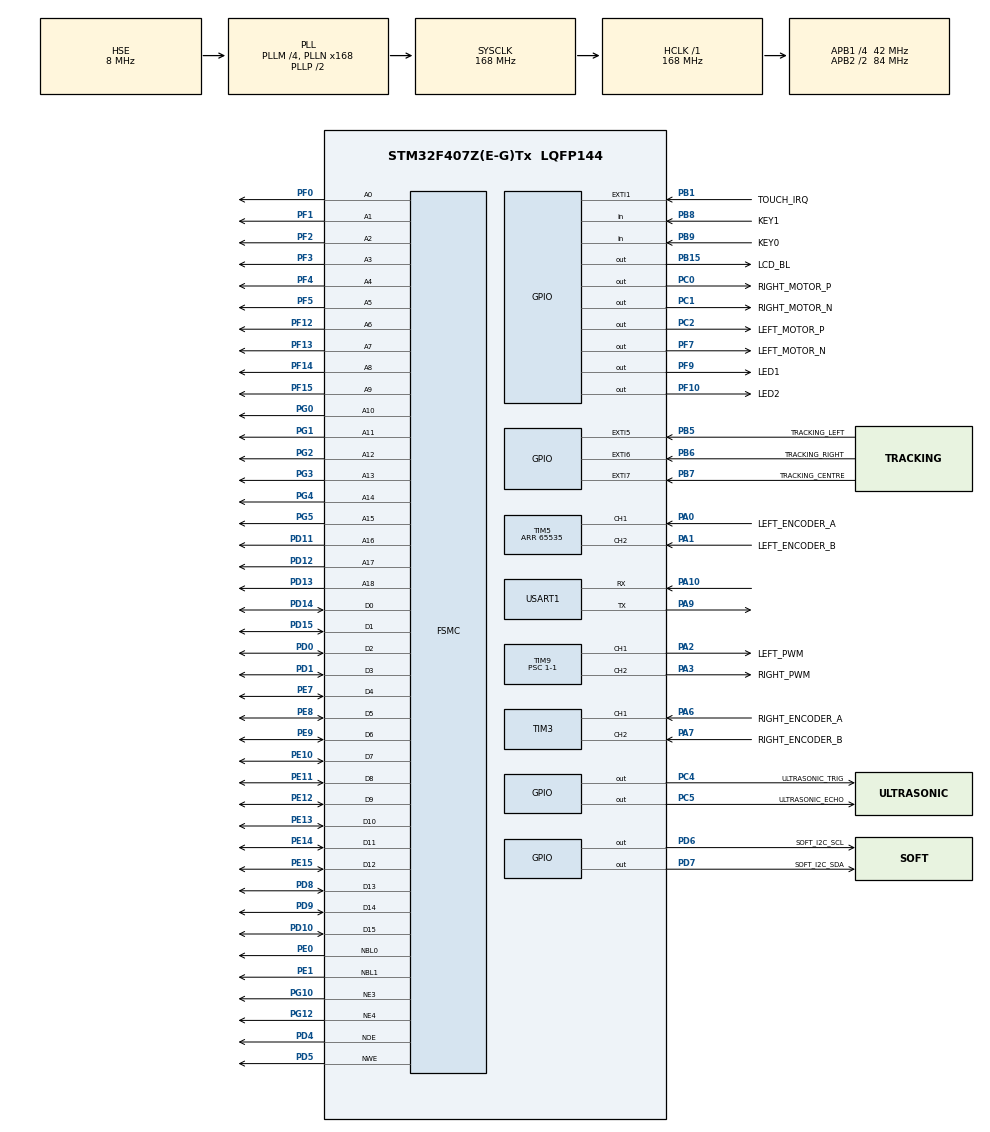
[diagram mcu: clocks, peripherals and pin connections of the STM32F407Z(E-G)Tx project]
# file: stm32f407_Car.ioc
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Dma.MEMTOMEM.0.Direction=DMA_MEMORY_TO_MEMORY
Dma.MEMTOMEM.0.FIFOMode=DMA_FIFOMODE_ENABLE
Dma.MEMTOMEM.0.FIFOThreshold=DMA_FIFO_THRESHOLD_FULL
Dma.MEMTOMEM.0.Instance=DMA2_Stream0
Dma.MEMTOMEM.0.MemBurst=DMA_MBURST_SINGLE
Dma.MEMTOMEM.0.MemDataAlignment=DMA_MDATAALIGN_HALFWORD
Dma.MEMTOMEM.0.MemInc=DMA_MINC_DISABLE
Dma.MEMTOMEM.0.Mode=DMA_NORMAL
Dma.MEMTOMEM.0.PeriphBurst=DMA_PBURST_SINGLE
Dma.MEMTOMEM.0.PeriphDataAlignment=DMA_PDATAALIGN_HALFWORD
Dma.MEMTOMEM.0.PeriphInc=DMA_PINC_ENABLE
Dma.MEMTOMEM.0.Priority=DMA_PRIORITY_HIGH
Dma.MEMTOMEM.1.Direction=DMA_MEMORY_TO_MEMORY
Dma.MEMTOMEM.1.FIFOMode=DMA_FIFOMODE_ENABLE
Dma.MEMTOMEM.1.FIFOThreshold=DMA_FIFO_THRESHOLD_FULL
Dma.MEMTOMEM.1.Instance=DMA2_Stream2
Dma.MEMTOMEM.1.MemBurst=DMA_MBURST_SINGLE
Dma.MEMTOMEM.1.MemDataAlignment=DMA_MDATAALIGN_HALFWORD
Dma.MEMTOMEM.1.MemInc=DMA_MINC_DISABLE
Dma.MEMTOMEM.1.Mode=DMA_NORMAL
Dma.MEMTOMEM.1.PeriphBurst=DMA_PBURST_SINGLE
Dma.MEMTOMEM.1.PeriphDataAlignment=DMA_PDATAALIGN_HALFWORD
Dma.MEMTOMEM.1.PeriphInc=DMA_PINC_ENABLE
Dma.MEMTOMEM.1.Priority=DMA_PRIORITY_HIGH
Dma.MEMTOMEM.2.Direction=DMA_MEMORY_TO_MEMORY
Dma.MEMTOMEM.2.FIFOMode=DMA_FIFOMODE_ENABLE
Dma.MEMTOMEM.2.FIFOThreshold=DMA_FIFO_THRESHOLD_FULL
Dma.MEMTOMEM.2.Instance=DMA2_Stream3
Dma.MEMTOMEM.2.MemBurst=DMA_MBURST_SINGLE
Dma.MEMTOMEM.2.MemDataAlignment=DMA_MDATAALIGN_HALFWORD
Dma.MEMTOMEM.2.MemInc=DMA_MINC_ENABLE
Dma.MEMTOMEM.2.Mode=DMA_NORMAL
Dma.MEMTOMEM.2.PeriphBurst=DMA_PBURST_SINGLE
Dma.MEMTOMEM.2.PeriphDataAlignment=DMA_PDATAALIGN_HALFWORD
Dma.MEMTOMEM.2.PeriphInc=DMA_PINC_ENABLE
Dma.MEMTOMEM.2.Priority=DMA_PRIORITY_HIGH
Dma.Request0=MEMTOMEM
Dma.Request1=MEMTOMEM
Dma.Request2=MEMTOMEM
FREERTOS.BinarySemaphores01=SemUartReceived,Dynamic,NULL
FREERTOS.Tasks01=defaultTask,0,128,StartDefaultTask,Default,NULL,Dynamic,NULL,NULL;DisplayTask,0,1024,StartDisplayTask,As external,NULL,Dynamic,NULL,NULL;UartTask,0,512,StartUartTask,As external,SemUartReceivedHandle,Dynamic,NULL,NULL;LoopTask,0,4096,StartLoopTask,As external,NULL,Dynamic,NULL,NULL;KeyTask,0,128,StartKeyTask,As external,NULL,Dynamic,NULL,NULL;CarTask,0,1024,StartCarTask,As external,NULL,Dynamic,NULL,NULL
FREERTOS.configTOTAL_HEAP_SIZE=32768
FREERTOS.configUSE_NEWLIB_REENTRANT=1
FREERTOS.configUSE_TIMERS=1
FSMC.AddressSetupTime1=5
FSMC.AddressSetupTime2=2
FSMC.BusTurnAroundDuration1=1
FSMC.BusTurnAroundDuration2=1
FSMC.DataSetupTime1=7
FSMC.DataSetupTime2=2
FSMC.ExtendedMode1=FSMC_EXTENDED_MODE_DISABLE
FSMC.WriteOperation1=FSMC_WRITE_OPERATION_ENABLE
Mcu.Family=STM32F4
Mcu.Name=STM32F407Z(E-G)Tx
Mcu.Package=LQFP144
Mcu.UserConstants=ENCODER_TICK_FREQ_DEFAULT,50
NVIC.EXTI1_IRQn=true\:5\:0\:false\:false\:true\:true\:true\:true
NVIC.PriorityGroup=NVIC_PRIORITYGROUP_4
NVIC.TIM1_UP_TIM10_IRQn=true\:15\:0\:false\:false\:true\:false\:false\:true
NVIC.TIM3_IRQn=true\:5\:0\:false\:false\:true\:true\:true\:true
NVIC.TIM5_IRQn=true\:5\:0\:false\:false\:true\:true\:true\:true
NVIC.TIM6_DAC_IRQn=true\:5\:0\:false\:false\:true\:true\:true\:true
NVIC.TIM7_IRQn=true\:5\:0\:false\:false\:true\:true\:true\:true
NVIC.TimeBase=TIM1_UP_TIM10_IRQn
NVIC.TimeBaseIP=TIM10
NVIC.USART1_IRQn=true\:5\:0\:false\:false\:true\:true\:true\:true
PA0-WKUP.GPIO_Label=LEFT_ENCODER_A
PA0-WKUP.GPIO_Speed=GPIO_SPEED_FREQ_VERY_HIGH
PA0-WKUP.Signal=S_TIM5_CH1
PA1.GPIO_Label=LEFT_ENCODER_B
PA1.GPIO_Speed=GPIO_SPEED_FREQ_VERY_HIGH
PA1.Signal=S_TIM5_CH2
PA10.Mode=Asynchronous
PA10.Signal=USART1_RX
PA13.Mode=Serial_Wire
PA13.Signal=SYS_JTMS-SWDIO
PA14.Mode=Serial_Wire
PA14.Signal=SYS_JTCK-SWCLK
PA2.GPIO_Label=LEFT_PWM
PA2.GPIO_Speed=GPIO_SPEED_FREQ_VERY_HIGH
PA2.Signal=S_TIM9_CH1
PA3.GPIO_Label=RIGHT_PWM
PA3.GPIO_Speed=GPIO_SPEED_FREQ_VERY_HIGH
PA3.Signal=S_TIM9_CH2
PA6.GPIO_Label=RIGHT_ENCODER_A
PA6.Signal=S_TIM3_CH1
PA7.GPIO_Label=RIGHT_ENCODER_B
PA7.Signal=S_TIM3_CH2
PA9.Mode=Asynchronous
PA9.Signal=USART1_TX
PB1.GPIO_Label=TOUCH_IRQ
PB1.GPIO_ModeDefaultEXTI=GPIO_MODE_IT_FALLING
PB1.GPIO_PuPd=GPIO_PULLUP
PB1.Signal=GPXTI1
PB15.GPIO_Label=LCD_BL
PB15.PinState=GPIO_PIN_RESET
PB15.Signal=GPIO_Output
PB5.GPIO_Label=TRACKING_LEFT
PB5.Signal=GPXTI5
PB6.GPIO_Label=TRACKING_RIGHT
PB6.Signal=GPXTI6
PB7.GPIO_Label=TRACKING_CENTRE
PB7.GPIO_ModeDefaultEXTI=GPIO_MODE_IT_FALLING
PB7.Signal=GPXTI7
PB8.GPIO_Label=KEY1
PB8.GPIO_PuPd=GPIO_PULLUP
PB8.Signal=GPIO_Input
PB9.GPIO_Label=KEY0
PB9.GPIO_PuPd=GPIO_PULLUP
PB9.Signal=GPIO_Input
PC0.GPIO_Label=RIGHT_MOTOR_P
PC0.GPIO_Speed=GPIO_SPEED_FREQ_HIGH
PC0.Signal=GPIO_Output
PC1.GPIO_Label=RIGHT_MOTOR_N
PC1.GPIO_Speed=GPIO_SPEED_FREQ_HIGH
PC1.Signal=GPIO_Output
PC14-OSC32_IN.Mode=LSE-External-Oscillator
PC14-OSC32_IN.Signal=RCC_OSC32_IN
PC15-OSC32_OUT.Mode=LSE-External-Oscillator
PC15-OSC32_OUT.Signal=RCC_OSC32_OUT
PC2.GPIO_Label=LEFT_MOTOR_P
PC2.Signal=GPIO_Output
PC4.GPIO_Label=ULTRASONIC_TRIG
PC4.GPIO_Speed=GPIO_SPEED_FREQ_HIGH
PC4.Signal=GPIO_Output
PC5.GPIO_Label=ULTRASONIC_ECHO
PC5.GPIO_Speed=GPIO_SPEED_FREQ_HIGH
PC5.Signal=GPIO_Output
PD0.Signal=FSMC_D2_DA2
PD1.Signal=FSMC_D3_DA3
PD10.Signal=FSMC_D15_DA15
PD11.Signal=FSMC_A16_CLE
PD12.Signal=FSMC_A17_ALE
PD13.Signal=FSMC_A18
PD14.Signal=FSMC_D0_DA0
PD15.Signal=FSMC_D1_DA1
PD4.Signal=FSMC_NOE
PD5.Signal=FSMC_NWE
PD6.GPIO_Label=SOFT_I2C_SCL
PD6.GPIO_ModeDefaultOutputPP=GPIO_MODE_OUTPUT_OD
PD6.GPIO_Speed=GPIO_SPEED_FREQ_VERY_HIGH
PD6.PinState=GPIO_PIN_SET
PD6.Signal=GPIO_Output
PD7.GPIO_Label=SOFT_I2C_SDA
PD7.GPIO_ModeDefaultOutputPP=GPIO_MODE_OUTPUT_OD
PD7.GPIO_Speed=GPIO_SPEED_FREQ_VERY_HIGH
PD7.PinState=GPIO_PIN_SET
PD7.Signal=GPIO_Output
PD8.Signal=FSMC_D13_DA13
PD9.Signal=FSMC_D14_DA14
PE0.Signal=FSMC_NBL0
PE1.Signal=FSMC_NBL1
PE10.Signal=FSMC_D7_DA7
PE11.Signal=FSMC_D8_DA8
PE12.Signal=FSMC_D9_DA9
PE13.Signal=FSMC_D10_DA10
PE14.Signal=FSMC_D11_DA11
PE15.Signal=FSMC_D12_DA12
PE7.Signal=FSMC_D4_DA4
PE8.Signal=FSMC_D5_DA5
PE9.Signal=FSMC_D6_DA6
PF0.Signal=FSMC_A0
PF1.Signal=FSMC_A1
PF10.GPIO_Label=LED2
PF10.PinState=GPIO_PIN_SET
PF10.Signal=GPIO_Output
PF12.Signal=FSMC_A6
PF13.Signal=FSMC_A7
PF14.Signal=FSMC_A8
PF15.Signal=FSMC_A9
PF2.Signal=FSMC_A2
PF3.Signal=FSMC_A3
PF4.Signal=FSMC_A4
PF5.Signal=FSMC_A5
PF7.GPIO_Label=LEFT_MOTOR_N
PF7.Signal=GPIO_Output
PF9.GPIO_Label=LED1
PF9.PinState=GPIO_PIN_SET
PF9.Signal=GPIO_Output
PG0.Signal=FSMC_A10
PG1.Signal=FSMC_A11
PG10.Mode=NorPsramChipSelect3_1
PG10.Signal=FSMC_NE3
PG12.Mode=NorPsramChipSelect4_2
PG12.Signal=FSMC_NE4
PG2.Signal=FSMC_A12
PG3.Signal=FSMC_A13
PG4.Signal=FSMC_A14
PG5.Signal=FSMC_A15
PH0-OSC_IN.Mode=HSE-External-Oscillator
PH0-OSC_IN.Signal=RCC_OSC_IN
PH1-OSC_OUT.Mode=HSE-External-Oscillator
PH1-OSC_OUT.Signal=RCC_OSC_OUT
ProjectManager.HeapSize=0x200
ProjectManager.StackSize=0x1000
ProjectManager.TargetToolchain=STM32CubeIDE
RCC.48MHZClocksFreq_Value=84000000
RCC.AHBFreq_Value=168000000
RCC.APB1CLKDivider=RCC_HCLK_DIV4
RCC.APB1Freq_Value=42000000
RCC.APB1TimFreq_Value=84000000
RCC.APB2CLKDivider=RCC_HCLK_DIV2
RCC.APB2Freq_Value=84000000
RCC.APB2TimFreq_Value=168000000
RCC.CortexFreq_Value=168000000
RCC.HCLKFreq_Value=168000000
RCC.HSE_VALUE=8000000
RCC.HSI_VALUE=16000000
RCC.PLLM=4
RCC.PLLN=168
RCC.PLLSourceVirtual=RCC_PLLSOURCE_HSE
RCC.RCC_RTC_Clock_SourceVirtual=RCC_RTCCLKSOURCE_LSE
RCC.SYSCLKFreq_VALUE=168000000
RCC.SYSCLKSource=RCC_SYSCLKSOURCE_PLLCLK
RCC.VCOOutputFreq_Value=336000000
RTC.Date=1
RTC.Format=RTC_FORMAT_BIN
RTC.Hours=10
RTC.Month=RTC_MONTH_JANUARY
RTC.WeekDay=RTC_WEEKDAY_MONDAY
RTC.Year=21
SH.FSMC_A0.0=FSMC_A0,19b-a1
SH.FSMC_A1.0=FSMC_A1,19b-a1
SH.FSMC_A10.0=FSMC_A10,19b-a1
SH.FSMC_A11.0=FSMC_A11,19b-a1
SH.FSMC_A12.0=FSMC_A12,19b-a1
SH.FSMC_A13.0=FSMC_A13,19b-a1
SH.FSMC_A14.0=FSMC_A14,19b-a1
SH.FSMC_A15.0=FSMC_A15,19b-a1
SH.FSMC_A16_CLE.0=FSMC_A16,19b-a1
SH.FSMC_A17_ALE.0=FSMC_A17,19b-a1
SH.FSMC_A18.0=FSMC_A18,19b-a1
SH.FSMC_A2.0=FSMC_A2,19b-a1
SH.FSMC_A3.0=FSMC_A3,19b-a1
SH.FSMC_A4.0=FSMC_A4,19b-a1
SH.FSMC_A5.0=FSMC_A5,19b-a1
SH.FSMC_A6.0=FSMC_A6,19b-a1
SH.FSMC_A6.1=FSMC_A6,A6_2
SH.FSMC_A7.0=FSMC_A7,19b-a1
SH.FSMC_A8.0=FSMC_A8,19b-a1
SH.FSMC_A9.0=FSMC_A9,19b-a1
SH.FSMC_D0_DA0.0=FSMC_D0,16b-d1
SH.FSMC_D0_DA0.1=FSMC_D0,16b-d2
SH.FSMC_D10_DA10.0=FSMC_D10,16b-d1
SH.FSMC_D10_DA10.1=FSMC_D10,16b-d2
SH.FSMC_D11_DA11.0=FSMC_D11,16b-d1
SH.FSMC_D11_DA11.1=FSMC_D11,16b-d2
SH.FSMC_D12_DA12.0=FSMC_D12,16b-d1
SH.FSMC_D12_DA12.1=FSMC_D12,16b-d2
SH.FSMC_D13_DA13.0=FSMC_D13,16b-d1
SH.FSMC_D13_DA13.1=FSMC_D13,16b-d2
SH.FSMC_D14_DA14.0=FSMC_D14,16b-d1
SH.FSMC_D14_DA14.1=FSMC_D14,16b-d2
SH.FSMC_D15_DA15.0=FSMC_D15,16b-d1
SH.FSMC_D15_DA15.1=FSMC_D15,16b-d2
SH.FSMC_D1_DA1.0=FSMC_D1,16b-d1
SH.FSMC_D1_DA1.1=FSMC_D1,16b-d2
SH.FSMC_D2_DA2.0=FSMC_D2,16b-d1
SH.FSMC_D2_DA2.1=FSMC_D2,16b-d2
SH.FSMC_D3_DA3.0=FSMC_D3,16b-d1
SH.FSMC_D3_DA3.1=FSMC_D3,16b-d2
SH.FSMC_D4_DA4.0=FSMC_D4,16b-d1
SH.FSMC_D4_DA4.1=FSMC_D4,16b-d2
SH.FSMC_D5_DA5.0=FSMC_D5,16b-d1
SH.FSMC_D5_DA5.1=FSMC_D5,16b-d2
SH.FSMC_D6_DA6.0=FSMC_D6,16b-d1
SH.FSMC_D6_DA6.1=FSMC_D6,16b-d2
SH.FSMC_D7_DA7.0=FSMC_D7,16b-d1
SH.FSMC_D7_DA7.1=FSMC_D7,16b-d2
SH.FSMC_D8_DA8.0=FSMC_D8,16b-d1
SH.FSMC_D8_DA8.1=FSMC_D8,16b-d2
SH.FSMC_D9_DA9.0=FSMC_D9,16b-d1
SH.FSMC_D9_DA9.1=FSMC_D9,16b-d2
SH.FSMC_NBL0.0=FSMC_NBL0,2ByteEnable1
SH.FSMC_NBL1.0=FSMC_NBL1,2ByteEnable1
SH.FSMC_NOE.0=FSMC_NOE,Sram1
SH.FSMC_NOE.1=FSMC_NOE,Lcd2
SH.FSMC_NWE.0=FSMC_NWE,Sram1
SH.FSMC_NWE.1=FSMC_NWE,Lcd2
SH.S_TIM3_CH1.0=TIM3_CH1,Encoder_Interface
SH.S_TIM3_CH2.0=TIM3_CH2,Encoder_Interface
SH.S_TIM5_CH1.0=TIM5_CH1,Encoder_Interface
SH.S_TIM5_CH2.0=TIM5_CH2,Encoder_Interface
SH.S_TIM9_CH1.0=TIM9_CH1,PWM Generation1 CH1
SH.S_TIM9_CH2.0=TIM9_CH2,PWM Generation2 CH2
STMicroelectronics.X-CUBE-TOUCHGFX.4.17.0.tgfx_address1=0x68000000
STMicroelectronics.X-CUBE-TOUCHGFX.4.17.0.tgfx_address2=0x68032000
STMicroelectronics.X-CUBE-TOUCHGFX.4.17.0.tgfx_buffering_strategy=Double
STMicroelectronics.X-CUBE-TOUCHGFX.4.17.0.tgfx_custom_height=400
STMicroelectronics.X-CUBE-TOUCHGFX.4.17.0.tgfx_custom_width=240
STMicroelectronics.X-CUBE-TOUCHGFX.4.17.0.tgfx_datareader=Disabled
STMicroelectronics.X-CUBE-TOUCHGFX.4.17.0.tgfx_display_interface=disp_fmc
STMicroelectronics.X-CUBE-TOUCHGFX.4.17.0.tgfx_fmc_base_address=0x6000007E
STMicroelectronics.X-CUBE-TOUCHGFX.4.17.0.tgfx_location=By Address
STMicroelectronics.X-CUBE-TOUCHGFX.4.17.0_IsPackSelfContextualization=true
TIM3.AutoReloadPreload=TIM_AUTORELOAD_PRELOAD_ENABLE
TIM3.EncoderMode=TIM_ENCODERMODE_TI12
TIM3.IC2Polarity=TIM_ICPOLARITY_RISING
TIM3.TIM_MasterOutputTrigger=TIM_TRGO_RESET
TIM5.AutoReloadPreload=TIM_AUTORELOAD_PRELOAD_ENABLE
TIM5.EncoderMode=TIM_ENCODERMODE_TI12
TIM5.IC2Polarity=TIM_ICPOLARITY_RISING
TIM5.Period=65535
TIM5.TIM_MasterOutputTrigger=TIM_TRGO_RESET
TIM6.AutoReloadPreload=TIM_AUTORELOAD_PRELOAD_ENABLE
TIM6.Period=ENCODER_TICK_FREQ_DEFAULT*10-1
TIM6.Prescaler=8400-1
TIM6.TIM_MasterOutputTrigger=TIM_TRGO_RESET
TIM7.AutoReloadPreload=TIM_AUTORELOAD_PRELOAD_ENABLE
TIM7.Prescaler=84-1
TIM7.TIM_MasterOutputTrigger=TIM_TRGO_UPDATE
TIM9.AutoReloadPreload=TIM_AUTORELOAD_PRELOAD_ENABLE
TIM9.Channel-PWM\ Generation1\ CH1=TIM_CHANNEL_1
TIM9.Channel-PWM\ Generation2\ CH2=TIM_CHANNEL_2
TIM9.Period=5600-1
TIM9.Prescaler=1-1
TIM9.Pulse-PWM\ Generation1\ CH1=0
TIM9.Pulse-PWM\ Generation2\ CH2=0
USART1.VirtualMode=VM_ASYNC
VP_FREERTOS_VS_CMSIS_V1.Mode=CMSIS_V1
VP_RTC_VS_RTC_Activate.Mode=RTC_Enabled
VP_RTC_VS_RTC_Calendar.Mode=RTC_Calendar
VP_SYS_VS_tim10.Mode=TIM10
VP_TIM6_VS_ClockSourceINT.Mode=Enable_Timer
VP_TIM7_VS_ClockSourceINT.Mode=Enable_Timer
board=custom

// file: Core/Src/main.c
/* USER CODE BEGIN Header */
/**
  ******************************************************************************
  * @file           : main.c
  * @brief          : Main program body
  ******************************************************************************
  * @attention
  *
  * <h2><center>&copy; Copyright (c) 2021 STMicroelectronics.
  * All rights reserved.</center></h2>
  *
  * This software component is licensed by ST under Ultimate Liberty license
  * SLA0044, the "License"; You may not use this file except in compliance with
  * the License. You may obtain a copy of the License at:
  *                             www.st.com/SLA0044
  *
  ******************************************************************************
  */
/* USER CODE END Header */
#include "main.h"
#include "cmsis_os.h"

/* USER CODE BEGIN Includes */
#include "mainpp.hpp"

/* USER CODE END Includes */

RTC_HandleTypeDef hrtc;

TIM_HandleTypeDef htim3;
TIM_HandleTypeDef htim5;
TIM_HandleTypeDef htim6;
TIM_HandleTypeDef htim7;
TIM_HandleTypeDef htim9;

UART_HandleTypeDef huart1;

DMA_HandleTypeDef hdma_memtomem_dma2_stream0;
DMA_HandleTypeDef hdma_memtomem_dma2_stream2;
DMA_HandleTypeDef hdma_memtomem_dma2_stream3;
SRAM_HandleTypeDef hsram1;
SRAM_HandleTypeDef hsram2;

osThreadId defaultTaskHandle;
osThreadId DisplayTaskHandle;
osThreadId UartTaskHandle;
osThreadId LoopTaskHandle;
osThreadId KeyTaskHandle;
osThreadId CarTaskHandle;
osSemaphoreId SemUartReceivedHandle;
/* USER CODE BEGIN PV */
//DCMI_HandleTypeDef *DCMI_Handle = &hdcmi;
RTC_HandleTypeDef *RtcHandle = &hrtc;
//I2C_HandleTypeDef *I2C_Handle = &hi2c1;
TIM_HandleTypeDef *usDelay_timer_Handle = &htim7;
UART_HandleTypeDef *UartHandle = &huart1;

Encoder_HandleTypeDef *RIGHT_encoder = &htim3;
Encoder_HandleTypeDef *LEFT_encoder = &htim5;
PWM_HandleTypeDef *LEFT_motor_pwm = &htim9;
PWM_HandleTypeDef *RIGHT_motor_pwm = &htim9;
TIM_HandleTypeDef *encoder_timer = &htim6;

/* USER CODE END PV */

void SystemClock_Config(void);
static void MX_GPIO_Init(void);
static void MX_TIM5_Init(void);
static void MX_FSMC_Init(void);
static void MX_TIM9_Init(void);
static void MX_DMA_Init(void);
static void MX_TIM7_Init(void);
static void MX_RTC_Init(void);
static void MX_TIM6_Init(void);
static void MX_USART1_UART_Init(void);
static void MX_TIM3_Init(void);
void StartDefaultTask(void const * argument);
extern void StartDisplayTask(void const * argument);
extern void StartUartTask(void const * argument);
extern void StartLoopTask(void const * argument);
extern void StartKeyTask(void const * argument);
extern void StartCarTask(void const * argument);

int main(void)
{

  /* MCU Configuration--------------------------------------------------------*/

  /* Reset of all peripherals, Initializes the Flash interface and the Systick. */
  HAL_Init();

  /* Configure the system clock */
  SystemClock_Config();

  /* Initialize all configured peripherals */
  MX_GPIO_Init();
  MX_TIM5_Init();
  MX_FSMC_Init();
  MX_TIM9_Init();
  MX_DMA_Init();
  MX_TIM7_Init();
  MX_RTC_Init();
  MX_TIM6_Init();
  MX_USART1_UART_Init();
  MX_TIM3_Init();
  /* USER CODE BEGIN 2 */
  setup();
  /* USER CODE END 2 */

  /* Create the semaphores(s) */
  /* definition and creation of SemUartReceived */
  osSemaphoreDef(SemUartReceived);
  SemUartReceivedHandle = osSemaphoreCreate(osSemaphore(SemUartReceived), 1);

  /* Create the thread(s) */
  /* definition and creation of defaultTask */
  osThreadDef(defaultTask, StartDefaultTask, osPriorityNormal, 0, 128);
  defaultTaskHandle = osThreadCreate(osThread(defaultTask), NULL);

  /* definition and creation of DisplayTask */
  osThreadDef(DisplayTask, StartDisplayTask, osPriorityNormal, 0, 1024);
  DisplayTaskHandle = osThreadCreate(osThread(DisplayTask), NULL);

  /* definition and creation of UartTask */
  osThreadDef(UartTask, StartUartTask, osPriorityNormal, 0, 512);
  UartTaskHandle = osThreadCreate(osThread(UartTask), (void*) SemUartReceivedHandle);

  /* definition and creation of LoopTask */
  osThreadDef(LoopTask, StartLoopTask, osPriorityNormal, 0, 4096);
  LoopTaskHandle = osThreadCreate(osThread(LoopTask), NULL);

  /* definition and creation of KeyTask */
  osThreadDef(KeyTask, StartKeyTask, osPriorityNormal, 0, 128);
  KeyTaskHandle = osThreadCreate(osThread(KeyTask), NULL);

  /* definition and creation of CarTask */
  osThreadDef(CarTask, StartCarTask, osPriorityNormal, 0, 1024);
  CarTaskHandle = osThreadCreate(osThread(CarTask), NULL);

  /* Start scheduler */
  osKernelStart();

  /* We should never get here as control is now taken by the scheduler */
  /* Infinite loop */
  while (1)
  {

  }
}

void SystemClock_Config(void)
{
  RCC_OscInitTypeDef RCC_OscInitStruct = {0};
  RCC_ClkInitTypeDef RCC_ClkInitStruct = {0};

  /** Configure the main internal regulator output voltage
  */
  __HAL_RCC_PWR_CLK_ENABLE();
  __HAL_PWR_VOLTAGESCALING_CONFIG(PWR_REGULATOR_VOLTAGE_SCALE1);
  /** Initializes the RCC Oscillators according to the specified parameters
  * in the RCC_OscInitTypeDef structure.
  */
  RCC_OscInitStruct.OscillatorType = RCC_OSCILLATORTYPE_HSE|RCC_OSCILLATORTYPE_LSE;
  RCC_OscInitStruct.HSEState = RCC_HSE_ON;
  RCC_OscInitStruct.LSEState = RCC_LSE_ON;
  RCC_OscInitStruct.PLL.PLLState = RCC_PLL_ON;
  RCC_OscInitStruct.PLL.PLLSource = RCC_PLLSOURCE_HSE;
  RCC_OscInitStruct.PLL.PLLM = 4;
  RCC_OscInitStruct.PLL.PLLN = 168;
  RCC_OscInitStruct.PLL.PLLP = RCC_PLLP_DIV2;
  RCC_OscInitStruct.PLL.PLLQ = 4;
  if (HAL_RCC_OscConfig(&RCC_OscInitStruct) != HAL_OK)
  {
    Error_Handler();
  }
  /** Initializes the CPU, AHB and APB buses clocks
  */
  RCC_ClkInitStruct.ClockType = RCC_CLOCKTYPE_HCLK|RCC_CLOCKTYPE_SYSCLK
                              |RCC_CLOCKTYPE_PCLK1|RCC_CLOCKTYPE_PCLK2;
  RCC_ClkInitStruct.SYSCLKSource = RCC_SYSCLKSOURCE_PLLCLK;
  RCC_ClkInitStruct.AHBCLKDivider = RCC_SYSCLK_DIV1;
  RCC_ClkInitStruct.APB1CLKDivider = RCC_HCLK_DIV4;
  RCC_ClkInitStruct.APB2CLKDivider = RCC_HCLK_DIV2;

  if (HAL_RCC_ClockConfig(&RCC_ClkInitStruct, FLASH_LATENCY_5) != HAL_OK)
  {
    Error_Handler();
  }
}

static void MX_RTC_Init(void)
{

  RTC_TimeTypeDef sTime = {0};
  RTC_DateTypeDef sDate = {0};

  /** Initialize RTC Only
  */
  hrtc.Instance = RTC;
  hrtc.Init.HourFormat = RTC_HOURFORMAT_24;
  hrtc.Init.AsynchPrediv = 127;
  hrtc.Init.SynchPrediv = 255;
  hrtc.Init.OutPut = RTC_OUTPUT_DISABLE;
  hrtc.Init.OutPutPolarity = RTC_OUTPUT_POLARITY_HIGH;
  hrtc.Init.OutPutType = RTC_OUTPUT_TYPE_OPENDRAIN;
  if (HAL_RTC_Init(&hrtc) != HAL_OK)
  {
    Error_Handler();
  }

  /** Initialize RTC and set the Time and Date
  */
  sTime.Hours = 10;
  sTime.Minutes = 0;
  sTime.Seconds = 0;
  sTime.DayLightSaving = RTC_DAYLIGHTSAVING_NONE;
  sTime.StoreOperation = RTC_STOREOPERATION_RESET;
  if (HAL_RTC_SetTime(&hrtc, &sTime, RTC_FORMAT_BIN) != HAL_OK)
  {
    Error_Handler();
  }
  sDate.WeekDay = RTC_WEEKDAY_MONDAY;
  sDate.Month = RTC_MONTH_JANUARY;
  sDate.Date = 1;
  sDate.Year = 21;

  if (HAL_RTC_SetDate(&hrtc, &sDate, RTC_FORMAT_BIN) != HAL_OK)
  {
    Error_Handler();
  }

}

static void MX_TIM3_Init(void)
{

  TIM_Encoder_InitTypeDef sConfig = {0};
  TIM_MasterConfigTypeDef sMasterConfig = {0};

  htim3.Instance = TIM3;
  htim3.Init.Prescaler = 0;
  htim3.Init.CounterMode = TIM_COUNTERMODE_UP;
  htim3.Init.Period = 65535;
  htim3.Init.ClockDivision = TIM_CLOCKDIVISION_DIV1;
  htim3.Init.AutoReloadPreload = TIM_AUTORELOAD_PRELOAD_ENABLE;
  sConfig.EncoderMode = TIM_ENCODERMODE_TI12;
  sConfig.IC1Polarity = TIM_ICPOLARITY_RISING;
  sConfig.IC1Selection = TIM_ICSELECTION_DIRECTTI;
  sConfig.IC1Prescaler = TIM_ICPSC_DIV1;
  sConfig.IC1Filter = 0;
  sConfig.IC2Polarity = TIM_ICPOLARITY_RISING;
  sConfig.IC2Selection = TIM_ICSELECTION_DIRECTTI;
  sConfig.IC2Prescaler = TIM_ICPSC_DIV1;
  sConfig.IC2Filter = 0;
  if (HAL_TIM_Encoder_Init(&htim3, &sConfig) != HAL_OK)
  {
    Error_Handler();
  }
  sMasterConfig.MasterOutputTrigger = TIM_TRGO_RESET;
  sMasterConfig.MasterSlaveMode = TIM_MASTERSLAVEMODE_DISABLE;
  if (HAL_TIMEx_MasterConfigSynchronization(&htim3, &sMasterConfig) != HAL_OK)
  {
    Error_Handler();
  }

}

static void MX_TIM5_Init(void)
{

  TIM_Encoder_InitTypeDef sConfig = {0};
  TIM_MasterConfigTypeDef sMasterConfig = {0};

  htim5.Instance = TIM5;
  htim5.Init.Prescaler = 0;
  htim5.Init.CounterMode = TIM_COUNTERMODE_UP;
  htim5.Init.Period = 65535;
  htim5.Init.ClockDivision = TIM_CLOCKDIVISION_DIV1;
  htim5.Init.AutoReloadPreload = TIM_AUTORELOAD_PRELOAD_ENABLE;
  sConfig.EncoderMode = TIM_ENCODERMODE_TI12;
  sConfig.IC1Polarity = TIM_ICPOLARITY_RISING;
  sConfig.IC1Selection = TIM_ICSELECTION_DIRECTTI;
  sConfig.IC1Prescaler = TIM_ICPSC_DIV1;
  sConfig.IC1Filter = 0;
  sConfig.IC2Polarity = TIM_ICPOLARITY_RISING;
  sConfig.IC2Selection = TIM_ICSELECTION_DIRECTTI;
  sConfig.IC2Prescaler = TIM_ICPSC_DIV1;
  sConfig.IC2Filter = 0;
  if (HAL_TIM_Encoder_Init(&htim5, &sConfig) != HAL_OK)
  {
    Error_Handler();
  }
  sMasterConfig.MasterOutputTrigger = TIM_TRGO_RESET;
  sMasterConfig.MasterSlaveMode = TIM_MASTERSLAVEMODE_DISABLE;
  if (HAL_TIMEx_MasterConfigSynchronization(&htim5, &sMasterConfig) != HAL_OK)
  {
    Error_Handler();
  }

}

static void MX_TIM6_Init(void)
{

  TIM_MasterConfigTypeDef sMasterConfig = {0};

  htim6.Instance = TIM6;
  htim6.Init.Prescaler = 8400-1;
  htim6.Init.CounterMode = TIM_COUNTERMODE_UP;
  htim6.Init.Period = ENCODER_TICK_FREQ_DEFAULT*10-1;
  htim6.Init.AutoReloadPreload = TIM_AUTORELOAD_PRELOAD_ENABLE;
  if (HAL_TIM_Base_Init(&htim6) != HAL_OK)
  {
    Error_Handler();
  }
  sMasterConfig.MasterOutputTrigger = TIM_TRGO_RESET;
  sMasterConfig.MasterSlaveMode = TIM_MASTERSLAVEMODE_DISABLE;
  if (HAL_TIMEx_MasterConfigSynchronization(&htim6, &sMasterConfig) != HAL_OK)
  {
    Error_Handler();
  }

}

static void MX_TIM7_Init(void)
{

  TIM_MasterConfigTypeDef sMasterConfig = {0};

  htim7.Instance = TIM7;
  htim7.Init.Prescaler = 84-1;
  htim7.Init.CounterMode = TIM_COUNTERMODE_UP;
  htim7.Init.Period = 65535;
  htim7.Init.AutoReloadPreload = TIM_AUTORELOAD_PRELOAD_ENABLE;
  if (HAL_TIM_Base_Init(&htim7) != HAL_OK)
  {
    Error_Handler();
  }
  sMasterConfig.MasterOutputTrigger = TIM_TRGO_UPDATE;
  sMasterConfig.MasterSlaveMode = TIM_MASTERSLAVEMODE_DISABLE;
  if (HAL_TIMEx_MasterConfigSynchronization(&htim7, &sMasterConfig) != HAL_OK)
  {
    Error_Handler();
  }

}

static void MX_TIM9_Init(void)
{

  TIM_OC_InitTypeDef sConfigOC = {0};

  htim9.Instance = TIM9;
  htim9.Init.Prescaler = 1-1;
  htim9.Init.CounterMode = TIM_COUNTERMODE_UP;
  htim9.Init.Period = 5600-1;
  htim9.Init.ClockDivision = TIM_CLOCKDIVISION_DIV1;
  htim9.Init.AutoReloadPreload = TIM_AUTORELOAD_PRELOAD_ENABLE;
  if (HAL_TIM_PWM_Init(&htim9) != HAL_OK)
  {
    Error_Handler();
  }
  sConfigOC.OCMode = TIM_OCMODE_PWM1;
  sConfigOC.Pulse = 0;
  sConfigOC.OCPolarity = TIM_OCPOLARITY_HIGH;
  sConfigOC.OCFastMode = TIM_OCFAST_DISABLE;
  if (HAL_TIM_PWM_ConfigChannel(&htim9, &sConfigOC, TIM_CHANNEL_1) != HAL_OK)
  {
    Error_Handler();
  }
  if (HAL_TIM_PWM_ConfigChannel(&htim9, &sConfigOC, TIM_CHANNEL_2) != HAL_OK)
  {
    Error_Handler();
  }
  HAL_TIM_MspPostInit(&htim9);

}

static void MX_USART1_UART_Init(void)
{

  huart1.Instance = USART1;
  huart1.Init.BaudRate = 115200;
  huart1.Init.WordLength = UART_WORDLENGTH_8B;
  huart1.Init.StopBits = UART_STOPBITS_1;
  huart1.Init.Parity = UART_PARITY_NONE;
  huart1.Init.Mode = UART_MODE_TX_RX;
  huart1.Init.HwFlowCtl = UART_HWCONTROL_NONE;
  huart1.Init.OverSampling = UART_OVERSAMPLING_16;
  if (HAL_UART_Init(&huart1) != HAL_OK)
  {
    Error_Handler();
  }

}

static void MX_DMA_Init(void)
{

  /* DMA controller clock enable */
  __HAL_RCC_DMA2_CLK_ENABLE();

  /* Configure DMA request hdma_memtomem_dma2_stream0 on DMA2_Stream0 */
  hdma_memtomem_dma2_stream0.Instance = DMA2_Stream0;
  hdma_memtomem_dma2_stream0.Init.Channel = DMA_CHANNEL_0;
  hdma_memtomem_dma2_stream0.Init.Direction = DMA_MEMORY_TO_MEMORY;
  hdma_memtomem_dma2_stream0.Init.PeriphInc = DMA_PINC_ENABLE;
  hdma_memtomem_dma2_stream0.Init.MemInc = DMA_MINC_DISABLE;
  hdma_memtomem_dma2_stream0.Init.PeriphDataAlignment = DMA_PDATAALIGN_HALFWORD;
  hdma_memtomem_dma2_stream0.Init.MemDataAlignment = DMA_MDATAALIGN_HALFWORD;
  hdma_memtomem_dma2_stream0.Init.Mode = DMA_NORMAL;
  hdma_memtomem_dma2_stream0.Init.Priority = DMA_PRIORITY_HIGH;
  hdma_memtomem_dma2_stream0.Init.FIFOMode = DMA_FIFOMODE_ENABLE;
  hdma_memtomem_dma2_stream0.Init.FIFOThreshold = DMA_FIFO_THRESHOLD_FULL;
  hdma_memtomem_dma2_stream0.Init.MemBurst = DMA_MBURST_SINGLE;
  hdma_memtomem_dma2_stream0.Init.PeriphBurst = DMA_PBURST_SINGLE;
  if (HAL_DMA_Init(&hdma_memtomem_dma2_stream0) != HAL_OK)
  {
    Error_Handler( );
  }

  /* Configure DMA request hdma_memtomem_dma2_stream2 on DMA2_Stream2 */
  hdma_memtomem_dma2_stream2.Instance = DMA2_Stream2;
  hdma_memtomem_dma2_stream2.Init.Channel = DMA_CHANNEL_0;
  hdma_memtomem_dma2_stream2.Init.Direction = DMA_MEMORY_TO_MEMORY;
  hdma_memtomem_dma2_stream2.Init.PeriphInc = DMA_PINC_ENABLE;
  hdma_memtomem_dma2_stream2.Init.MemInc = DMA_MINC_DISABLE;
  hdma_memtomem_dma2_stream2.Init.PeriphDataAlignment = DMA_PDATAALIGN_HALFWORD;
  hdma_memtomem_dma2_stream2.Init.MemDataAlignment = DMA_MDATAALIGN_HALFWORD;
  hdma_memtomem_dma2_stream2.Init.Mode = DMA_NORMAL;
  hdma_memtomem_dma2_stream2.Init.Priority = DMA_PRIORITY_HIGH;
  hdma_memtomem_dma2_stream2.Init.FIFOMode = DMA_FIFOMODE_ENABLE;
  hdma_memtomem_dma2_stream2.Init.FIFOThreshold = DMA_FIFO_THRESHOLD_FULL;
  hdma_memtomem_dma2_stream2.Init.MemBurst = DMA_MBURST_SINGLE;
  hdma_memtomem_dma2_stream2.Init.PeriphBurst = DMA_PBURST_SINGLE;
  if (HAL_DMA_Init(&hdma_memtomem_dma2_stream2) != HAL_OK)
  {
    Error_Handler( );
  }

  /* Configure DMA request hdma_memtomem_dma2_stream3 on DMA2_Stream3 */
  hdma_memtomem_dma2_stream3.Instance = DMA2_Stream3;
  hdma_memtomem_dma2_stream3.Init.Channel = DMA_CHANNEL_0;
  hdma_memtomem_dma2_stream3.Init.Direction = DMA_MEMORY_TO_MEMORY;
  hdma_memtomem_dma2_stream3.Init.PeriphInc = DMA_PINC_ENABLE;
  hdma_memtomem_dma2_stream3.Init.MemInc = DMA_MINC_ENABLE;
  hdma_memtomem_dma2_stream3.Init.PeriphDataAlignment = DMA_PDATAALIGN_HALFWORD;
  hdma_memtomem_dma2_stream3.Init.MemDataAlignment = DMA_MDATAALIGN_HALFWORD;
  hdma_memtomem_dma2_stream3.Init.Mode = DMA_NORMAL;
  hdma_memtomem_dma2_stream3.Init.Priority = DMA_PRIORITY_HIGH;
  hdma_memtomem_dma2_stream3.Init.FIFOMode = DMA_FIFOMODE_ENABLE;
  hdma_memtomem_dma2_stream3.Init.FIFOThreshold = DMA_FIFO_THRESHOLD_FULL;
  hdma_memtomem_dma2_stream3.Init.MemBurst = DMA_MBURST_SINGLE;
  hdma_memtomem_dma2_stream3.Init.PeriphBurst = DMA_PBURST_SINGLE;
  if (HAL_DMA_Init(&hdma_memtomem_dma2_stream3) != HAL_OK)
  {
    Error_Handler( );
  }

}

static void MX_GPIO_Init(void)
{
  GPIO_InitTypeDef GPIO_InitStruct = {0};

  /* GPIO Ports Clock Enable */
  __HAL_RCC_GPIOC_CLK_ENABLE();
  __HAL_RCC_GPIOF_CLK_ENABLE();
  __HAL_RCC_GPIOH_CLK_ENABLE();
  __HAL_RCC_GPIOA_CLK_ENABLE();
  __HAL_RCC_GPIOB_CLK_ENABLE();
  __HAL_RCC_GPIOG_CLK_ENABLE();
  __HAL_RCC_GPIOE_CLK_ENABLE();
  __HAL_RCC_GPIOD_CLK_ENABLE();

  /*Configure GPIO pin Output Level */
  HAL_GPIO_WritePin(LEFT_MOTOR_N_GPIO_Port, LEFT_MOTOR_N_Pin, GPIO_PIN_RESET);

  /*Configure GPIO pin Output Level */
  HAL_GPIO_WritePin(GPIOF, LED1_Pin|LED2_Pin, GPIO_PIN_SET);

  /*Configure GPIO pin Output Level */
  HAL_GPIO_WritePin(GPIOC, RIGHT_MOTOR_P_Pin|RIGHT_MOTOR_N_Pin|LEFT_MOTOR_P_Pin|ULTRASONIC_TRIG_Pin
                          |ULTRASONIC_ECHO_Pin, GPIO_PIN_RESET);

  /*Configure GPIO pin Output Level */
  HAL_GPIO_WritePin(LCD_BL_GPIO_Port, LCD_BL_Pin, GPIO_PIN_RESET);

  /*Configure GPIO pin Output Level */
  HAL_GPIO_WritePin(GPIOD, SOFT_I2C_SCL_Pin|SOFT_I2C_SDA_Pin, GPIO_PIN_SET);

  /*Configure GPIO pins : LEFT_MOTOR_N_Pin LED1_Pin LED2_Pin */
  GPIO_InitStruct.Pin = LEFT_MOTOR_N_Pin|LED1_Pin|LED2_Pin;
  GPIO_InitStruct.Mode = GPIO_MODE_OUTPUT_PP;
  GPIO_InitStruct.Pull = GPIO_NOPULL;
  GPIO_InitStruct.Speed = GPIO_SPEED_FREQ_LOW;
  HAL_GPIO_Init(GPIOF, &GPIO_InitStruct);

  /*Configure GPIO pins : RIGHT_MOTOR_P_Pin RIGHT_MOTOR_N_Pin ULTRASONIC_TRIG_Pin ULTRASONIC_ECHO_Pin */
  GPIO_InitStruct.Pin = RIGHT_MOTOR_P_Pin|RIGHT_MOTOR_N_Pin|ULTRASONIC_TRIG_Pin|ULTRASONIC_ECHO_Pin;
  GPIO_InitStruct.Mode = GPIO_MODE_OUTPUT_PP;
  GPIO_InitStruct.Pull = GPIO_NOPULL;
  GPIO_InitStruct.Speed = GPIO_SPEED_FREQ_HIGH;
  HAL_GPIO_Init(GPIOC, &GPIO_InitStruct);

  /*Configure GPIO pin : LEFT_MOTOR_P_Pin */
  GPIO_InitStruct.Pin = LEFT_MOTOR_P_Pin;
  GPIO_InitStruct.Mode = GPIO_MODE_OUTPUT_PP;
  GPIO_InitStruct.Pull = GPIO_NOPULL;
  GPIO_InitStruct.Speed = GPIO_SPEED_FREQ_LOW;
  HAL_GPIO_Init(LEFT_MOTOR_P_GPIO_Port, &GPIO_InitStruct);

  /*Configure GPIO pin : TOUCH_IRQ_Pin */
  GPIO_InitStruct.Pin = TOUCH_IRQ_Pin;
  GPIO_InitStruct.Mode = GPIO_MODE_IT_FALLING;
  GPIO_InitStruct.Pull = GPIO_PULLUP;
  HAL_GPIO_Init(TOUCH_IRQ_GPIO_Port, &GPIO_InitStruct);

  /*Configure GPIO pin : LCD_BL_Pin */
  GPIO_InitStruct.Pin = LCD_BL_Pin;
  GPIO_InitStruct.Mode = GPIO_MODE_OUTPUT_PP;
  GPIO_InitStruct.Pull = GPIO_NOPULL;
  GPIO_InitStruct.Speed = GPIO_SPEED_FREQ_LOW;
  HAL_GPIO_Init(LCD_BL_GPIO_Port, &GPIO_InitStruct);

  /*Configure GPIO pins : SOFT_I2C_SCL_Pin SOFT_I2C_SDA_Pin */
  GPIO_InitStruct.Pin = SOFT_I2C_SCL_Pin|SOFT_I2C_SDA_Pin;
  GPIO_InitStruct.Mode = GPIO_MODE_OUTPUT_OD;
  GPIO_InitStruct.Pull = GPIO_NOPULL;
  GPIO_InitStruct.Speed = GPIO_SPEED_FREQ_VERY_HIGH;
  HAL_GPIO_Init(GPIOD, &GPIO_InitStruct);

  /*Configure GPIO pins : TRACKING_LEFT_Pin TRACKING_RIGHT_Pin */
  GPIO_InitStruct.Pin = TRACKING_LEFT_Pin|TRACKING_RIGHT_Pin;
  GPIO_InitStruct.Mode = GPIO_MODE_IT_RISING;
  GPIO_InitStruct.Pull = GPIO_NOPULL;
  HAL_GPIO_Init(GPIOB, &GPIO_InitStruct);

  /*Configure GPIO pin : TRACKING_CENTRE_Pin */
  GPIO_InitStruct.Pin = TRACKING_CENTRE_Pin;
  GPIO_InitStruct.Mode = GPIO_MODE_IT_FALLING;
  GPIO_InitStruct.Pull = GPIO_NOPULL;
  HAL_GPIO_Init(TRACKING_CENTRE_GPIO_Port, &GPIO_InitStruct);

  /*Configure GPIO pins : KEY1_Pin KEY0_Pin */
  GPIO_InitStruct.Pin = KEY1_Pin|KEY0_Pin;
  GPIO_InitStruct.Mode = GPIO_MODE_INPUT;
  GPIO_InitStruct.Pull = GPIO_PULLUP;
  HAL_GPIO_Init(GPIOB, &GPIO_InitStruct);

  /* EXTI interrupt init*/
  HAL_NVIC_SetPriority(EXTI1_IRQn, 5, 0);
  HAL_NVIC_EnableIRQ(EXTI1_IRQn);

}

/* FSMC initialization function */
static void MX_FSMC_Init(void)
{

  FSMC_NORSRAM_TimingTypeDef Timing = {0};

  /** Perform the SRAM1 memory initialization sequence
  */
  hsram1.Instance = FSMC_NORSRAM_DEVICE;
  hsram1.Extended = FSMC_NORSRAM_EXTENDED_DEVICE;
  /* hsram1.Init */
  hsram1.Init.NSBank = FSMC_NORSRAM_BANK3;
  hsram1.Init.DataAddressMux = FSMC_DATA_ADDRESS_MUX_DISABLE;
  hsram1.Init.MemoryType = FSMC_MEMORY_TYPE_SRAM;
  hsram1.Init.MemoryDataWidth = FSMC_NORSRAM_MEM_BUS_WIDTH_16;
  hsram1.Init.BurstAccessMode = FSMC_BURST_ACCESS_MODE_DISABLE;
  hsram1.Init.WaitSignalPolarity = FSMC_WAIT_SIGNAL_POLARITY_LOW;
  hsram1.Init.WrapMode = FSMC_WRAP_MODE_DISABLE;
  hsram1.Init.WaitSignalActive = FSMC_WAIT_TIMING_BEFORE_WS;
  hsram1.Init.WriteOperation = FSMC_WRITE_OPERATION_ENABLE;
  hsram1.Init.WaitSignal = FSMC_WAIT_SIGNAL_DISABLE;
  hsram1.Init.ExtendedMode = FSMC_EXTENDED_MODE_DISABLE;
  hsram1.Init.AsynchronousWait = FSMC_ASYNCHRONOUS_WAIT_DISABLE;
  hsram1.Init.WriteBurst = FSMC_WRITE_BURST_DISABLE;
  hsram1.Init.PageSize = FSMC_PAGE_SIZE_NONE;
  /* Timing */
  Timing.AddressSetupTime = 5;
  Timing.AddressHoldTime = 15;
  Timing.DataSetupTime = 7;
  Timing.BusTurnAroundDuration = 1;
  Timing.CLKDivision = 16;
  Timing.DataLatency = 17;
  Timing.AccessMode = FSMC_ACCESS_MODE_A;
  /* ExtTiming */

  if (HAL_SRAM_Init(&hsram1, &Timing, NULL) != HAL_OK)
  {
    Error_Handler( );
  }

  /** Perform the SRAM2 memory initialization sequence
  */
  hsram2.Instance = FSMC_NORSRAM_DEVICE;
  hsram2.Extended = FSMC_NORSRAM_EXTENDED_DEVICE;
  /* hsram2.Init */
  hsram2.Init.NSBank = FSMC_NORSRAM_BANK4;
  hsram2.Init.DataAddressMux = FSMC_DATA_ADDRESS_MUX_DISABLE;
  hsram2.Init.MemoryType = FSMC_MEMORY_TYPE_SRAM;
  hsram2.Init.MemoryDataWidth = FSMC_NORSRAM_MEM_BUS_WIDTH_16;
  hsram2.Init.BurstAccessMode = FSMC_BURST_ACCESS_MODE_DISABLE;
  hsram2.Init.WaitSignalPolarity = FSMC_WAIT_SIGNAL_POLARITY_LOW;
  hsram2.Init.WrapMode = FSMC_WRAP_MODE_DISABLE;
  hsram2.Init.WaitSignalActive = FSMC_WAIT_TIMING_BEFORE_WS;
  hsram2.Init.WriteOperation = FSMC_WRITE_OPERATION_ENABLE;
  hsram2.Init.WaitSignal = FSMC_WAIT_SIGNAL_DISABLE;
  hsram2.Init.ExtendedMode = FSMC_EXTENDED_MODE_DISABLE;
  hsram2.Init.AsynchronousWait = FSMC_ASYNCHRONOUS_WAIT_DISABLE;
  hsram2.Init.WriteBurst = FSMC_WRITE_BURST_DISABLE;
  hsram2.Init.PageSize = FSMC_PAGE_SIZE_NONE;
  /* Timing */
  Timing.AddressSetupTime = 2;
  Timing.AddressHoldTime = 15;
  Timing.DataSetupTime = 2;
  Timing.BusTurnAroundDuration = 1;
  Timing.CLKDivision = 16;
  Timing.DataLatency = 17;
  Timing.AccessMode = FSMC_ACCESS_MODE_A;
  /* ExtTiming */

  if (HAL_SRAM_Init(&hsram2, &Timing, NULL) != HAL_OK)
  {
    Error_Handler( );
  }

}

void StartDefaultTask(void const * argument)
{
  /* USER CODE BEGIN 5 */
  /* Infinite loop */
  for(;;)
  {
    LEDTask();
  }
  /* USER CODE END 5 */
}

void HAL_TIM_PeriodElapsedCallback(TIM_HandleTypeDef *htim)
{
  if (htim->Instance == TIM10) {
    HAL_IncTick();
  }
  /* USER CODE BEGIN Callback 1 */
  TIM_PeriodElapsedCallback(htim);
  /* USER CODE END Callback 1 */
}

void Error_Handler(void)
{
  __disable_irq();
  while (1)
  {
  }
}

/************************ (C) COPYRIGHT STMicroelectronics *****END OF FILE****/
